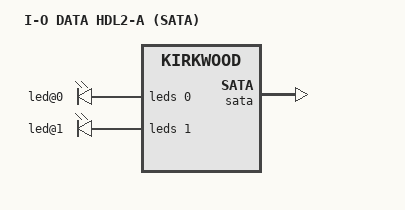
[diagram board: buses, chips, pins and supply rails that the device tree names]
// SPDX-License-Identifier: GPL-2.0-or-later OR MIT

#include <dt-bindings/leds/common.h>
#include "kirkwood-hdlx-a.dtsi"

/ {
	model = "I-O DATA HDL2-A (SATA)";
	compatible = "iodata,hdl2-a-sata", "marvell,kirkwood-88f6282", "marvell,kirkwood";

	chosen {
		/*
		 * The kernel and rootfs are stored to the storage
		 * connected SATA port (port1 or port2) or USB port.
		 * The path to the partition (/dev/sdXN) which contains
		 * root data will be assigned dynamically, GPT partition
		 * UUID or MSDOS signature is required instead.
		 */
		bootargs-append = " earlycon root=PARTUUID=5452574f-2211-4433-5566-778899aabb02 rootwait=20";
	};
};

&leds {
	led@0 {
		reg = <0>;
		color = <LED_COLOR_ID_RED>;
		function = LED_FUNCTION_DISK_ERR;
		function-enumerator = <1>;
	};

	led@1 {
		reg = <1>;
		color = <LED_COLOR_ID_RED>;
		function = LED_FUNCTION_DISK_ERR;
		function-enumerator = <2>;
	};
};

&mcu {
	iodata,landisk-r8c-model = "HDL2-A";
};

&sata {
	status = "okay";
	nr-ports = <2>;
};
